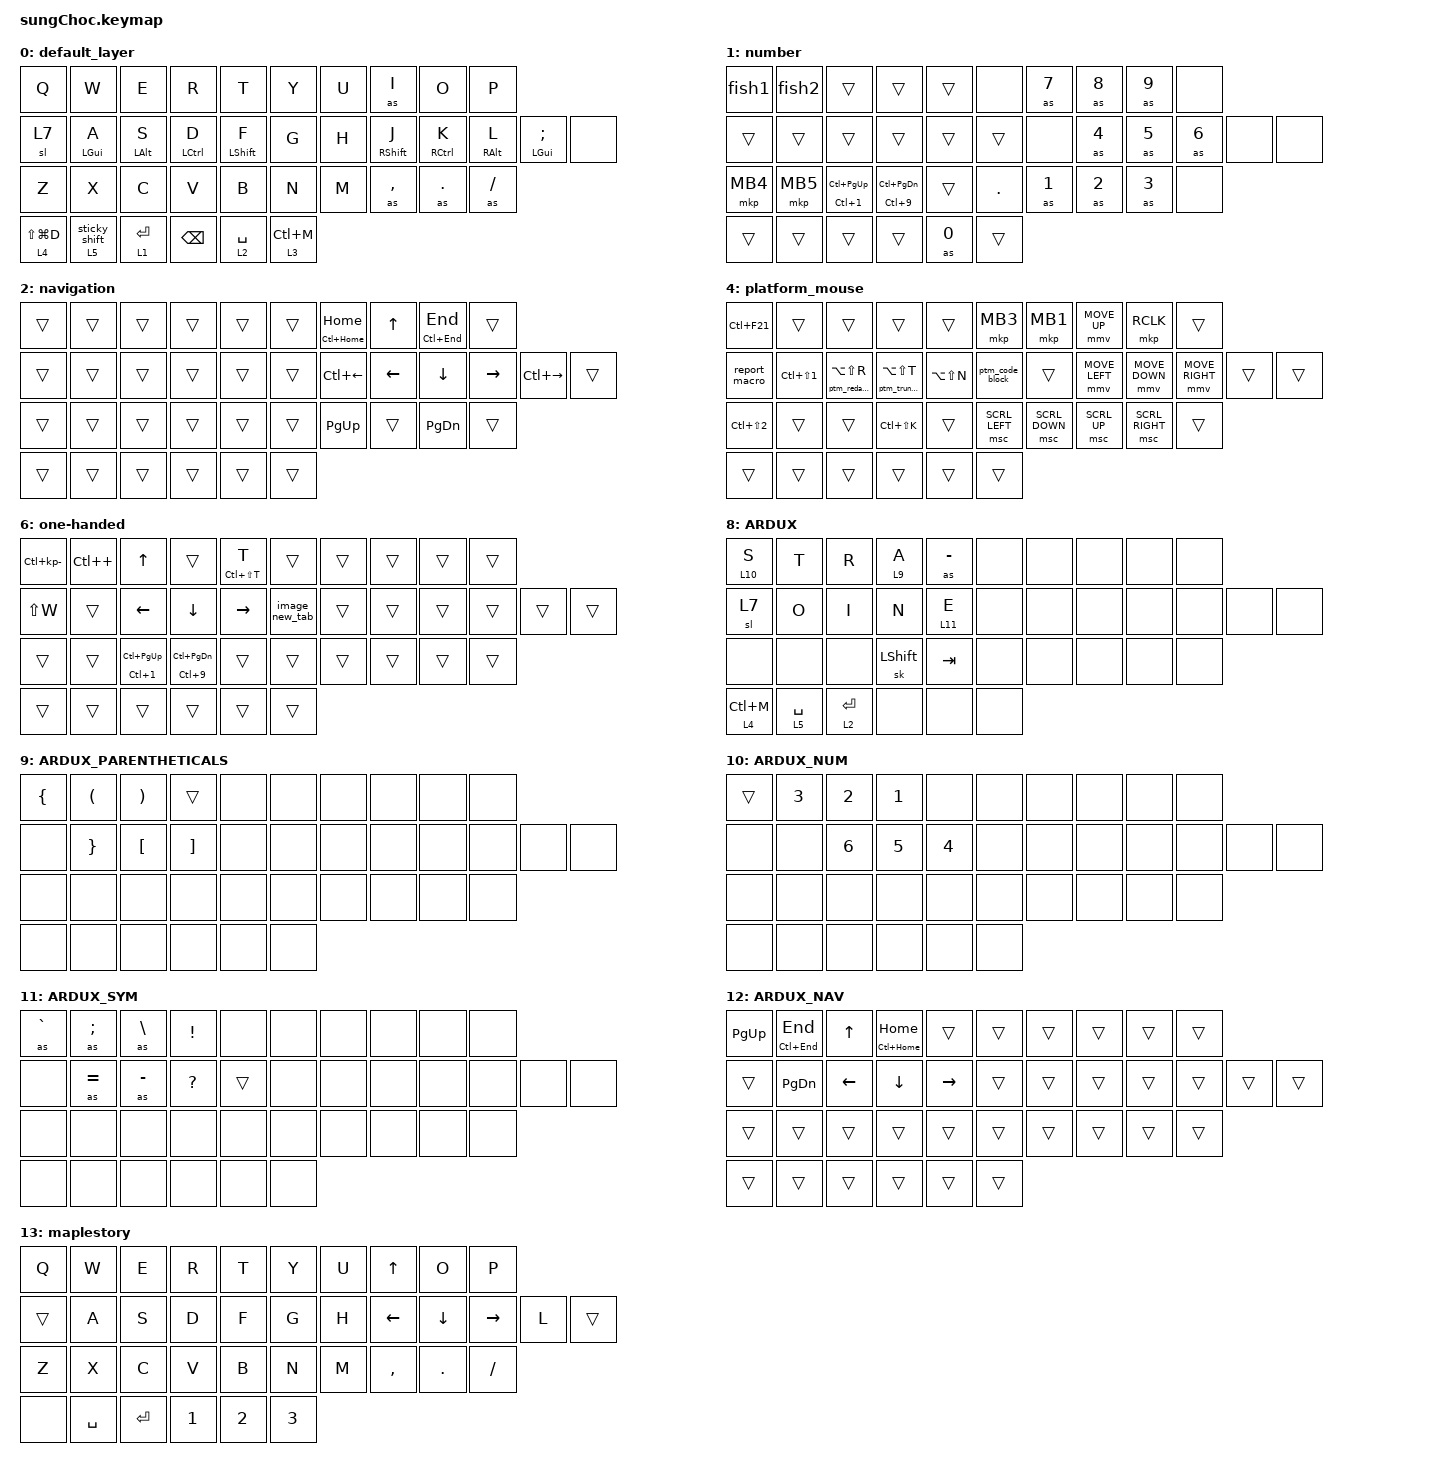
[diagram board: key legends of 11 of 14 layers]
#define ZMK_POINTING_DEFAULT_MOVE_VAL 700  // default: 600
#define ZMK_POINTING_DEFAULT_SCRL_VAL 15    // default: 10

#include <behaviors.dtsi>
#include <dt-bindings/zmk/keys.h>
#include <dt-bindings/zmk/pointing.h>

&sk { quick-release; };

&lt {
    quick-tap-ms = <150>;
    tapping-term-ms = <250>;
};

/ {
    behaviors {
        hrm: hrm {
            compatible = "zmk,behavior-hold-tap";
            label = "HRM";
            bindings = <&kp>, <&kp>;

            #binding-cells = <2>;
            tapping-term-ms = <280>;
            quick-tap-ms = <175>;
            require-prior-idle-ms = <150>;
            flavor = "balanced";
            hold-trigger-on-release;
        };

        ht_layer: ht_layer {
            compatible = "zmk,behavior-hold-tap";
            label = "HT_LAYER";
            bindings = <&mo>, <&kp>;

            #binding-cells = <2>;
            tapping-term-ms = <200>;
            quick-tap-ms = <175>;
            flavor = "tap-preferred";
        };

        hold_tap: hold_tap {
            compatible = "zmk,behavior-hold-tap";
            label = "HOLD_TAP";
            bindings = <&kp>, <&kp>;

            #binding-cells = <2>;
            tapping-term-ms = <180>;
            flavor = "balanced";
        };

        as_ht: auto_shift_hold_tap {
            compatible = "zmk,behavior-hold-tap";
            label = "AUTO_SHIFT_HOLD_TAP";
            bindings = <&shift>, <&kp>;

            #binding-cells = <2>;
            tapping-term-ms = <200>;
            flavor = "balanced";
        };

        burp_rep: burp_rep {
            compatible = "zmk,behavior-tap-dance";
            label = "BURP_REP";
            #binding-cells = <0>;
            bindings = <&kp LC(LS(R))>, <&kp LC(R)>;

            tapping-term-ms = <300>;
        };

        burp_proxy: burp_proxy {
            compatible = "zmk,behavior-tap-dance";
            label = "BURP_PROXY";
            #binding-cells = <0>;
            bindings = <&kp LS(LC(P))>, <&kp LC(T)>;

            tapping-term-ms = <300>;
        };

        burp_org: burp_org {
            compatible = "zmk,behavior-tap-dance";
            label = "BURP_ORG";
            #binding-cells = <0>;
            bindings = <&kp LC(LS(O))>, <&kp LC(O)>;

            tapping-term-ms = <300>;
        };

        burp_int: burp_int {
            compatible = "zmk,behavior-tap-dance";
            label = "BURP_INT";
            #binding-cells = <0>;
            bindings = <&hold_tap LC(P) LC(LS(I))>, <&kp LC(I)>;

            tapping-term-ms = <300>;
        };

        burp_send: burp_send {
            compatible = "zmk,behavior-tap-dance";
            label = "BURP_SEND";
            #binding-cells = <0>;
            bindings = <&kp LC(SPACE)>, <&kp LC(LS(SPACE))>;

            tapping-term-ms = <300>;
        };

        burp_dash: burp_dash {
            compatible = "zmk,behavior-tap-dance";
            label = "BURP_DASH";
            #binding-cells = <0>;
            bindings = <&hold_tap LC(LS(N9)) LS(LC(D))>, <&kp LC(LS(T))>;

            tapping-term-ms = <300>;
        };

        burp_fwd: burp_fwd {
            compatible = "zmk,behavior-tap-dance";
            label = "BURP_FWD";
            #binding-cells = <0>;
            bindings = <&kp LC(F)>, <&kp LC(LS(F))>;

            tapping-term-ms = <300>;
        };

        burp_notes_htmlE: burp_notes_htmlE {
            compatible = "zmk,behavior-tap-dance";
            label = "BURP_NOTES_HTMLE";
            #binding-cells = <0>;
            bindings = <&kp LC(LA(N))>, <&kp LC(LA(H))>;

            tapping-term-ms = <300>;
        };

        ac_vm: ac_vm {
            compatible = "zmk,behavior-tap-dance";
            label = "AC_VM";
            #binding-cells = <0>;
            bindings = <&kp LA(LS(LC(W)))>, <&kp LS(LC(LA(I)))>;
        };

        ac_browser: ac_browser {
            compatible = "zmk,behavior-tap-dance";
            label = "AC_BROWSER";
            #binding-cells = <0>;
            bindings =
                <&hold_tap LC(LA(LS(V))) LC(LA(LS(Q)))>,
                <&kp LA(LS(LC(X)))>;
        };

        truncate: truncate {
            compatible = "zmk,behavior-hold-tap";
            label = "TRUNCATE";
            bindings = <&ptm_truncated>, <&kp>;

            #binding-cells = <2>;
            tapping-term-ms = <180>;
        };

        redact: redact {
            compatible = "zmk,behavior-hold-tap";
            label = "REDACT";
            bindings = <&ptm_redacted>, <&kp>;

            #binding-cells = <2>;
            tapping-term-ms = <180>;
        };

        ptm_code_block: ptm_code_block {
            compatible = "zmk,behavior-tap-dance";
            label = "PTM_CODE_BLOCK";
            #binding-cells = <0>;
            bindings = <&ptm_request>, <&ptm_response>;
        };

        caps: caps {
            compatible = "zmk,behavior-hold-tap";
            label = "CAPS";
            bindings = <&caps_word>, <&sk>;

            #binding-cells = <2>;
            tapping-term-ms = <200>;
            flavor = "balanced";
        };

        ps_at: ps_at {
            compatible = "zmk,behavior-hold-tap";
            label = "PS_AT";
            bindings = <&kp>, <&alt_tab>;

            #binding-cells = <2>;
            tapping-term-ms = <200>;
        };

        burp_rep_with_shift: burp_rep_with_shift {
            compatible = "zmk,behavior-hold-tap";
            label = "BURP_REP_WITH_SHIFT";
            bindings = <&kp>, <&burp_rep>;

            #binding-cells = <2>;
            tapping-term-ms = <200>;
            flavor = "balanced";
        };

        sticky_OS_layer: sticky_OS_layer {
            compatible = "zmk,behavior-hold-tap";
            label = "STICKY_OS_LAYER";
            bindings = <&mo>, <&sl>;

            #binding-cells = <2>;
            tapping-term-ms = <200>;
            flavor = "balanced";
        };

        burp_layer_toggle: burp_layer_toggle {
            compatible = "zmk,behavior-tap-dance";
            label = "BURP_LAYER_TOGGLE";
            #binding-cells = <0>;
            bindings = <&ht_layer 5 A>, <&tog 5>;
        };

        fz_left_both: fz_left_both {
            compatible = "zmk,behavior-hold-tap";
            label = "FZ_LEFT_BOTH";
            bindings = <&kp>, <&fz_left>;

            #binding-cells = <2>;
            tapping-term-ms = <200>;
            flavor = "balanced";
        };

        ardux_sk: ardux_sk {
            compatible = "zmk,behavior-sticky-key";
            label = "ARDUX_SK";
            bindings = <&kp>;
            #binding-cells = <1>;
            release-after-ms = <3000>;
            ignore-modifiers;
        };

        os_shift_layer_change: os_shift_layer_change {
            compatible = "zmk,behavior-hold-tap";
            label = "OS_SHIFT_LAYER_CHANGE";
            bindings = <&mo>, <&sticky_shift>;

            #binding-cells = <2>;
            tapping-term-ms = <200>;
            flavor = "balanced";
        };
    };

    combos {
        compatible = "zmk,combos";

        esc {
            bindings = <&kp ESCAPE>;
            key-positions = <0 1>;
            require-prior-idle-ms = <200>;
            layers = <0 6>;
        };

        tasks {
            bindings = <&kp LC(LA(TAB))>;
            key-positions = <22 24>;
            require-prior-idle-ms = <200>;
        };

        cp {
            bindings = <&kp LC(C)>;
            key-positions = <23 24>;
            require-prior-idle-ms = <200>;
        };

        pst {
            bindings = <&hrm LC(LS(V)) LC(V)>;
            key-positions = <24 25>;
            require-prior-idle-ms = <200>;
        };

        minus {
            bindings = <&as MINUS>;
            key-positions = <8 9 7>;
        };

        quotes {
            bindings = <&as APOS>;
            key-positions = <19 20 18>;
        };

        fwslash {
            bindings = <&as BACKSLASH>;
            key-positions = <30 31 29>;
            require-prior-idle-ms = <200>;
        };

        lbracket {
            bindings = <&as LEFT_BRACKET>;
            key-positions = <3 4>;
            require-prior-idle-ms = <200>;
            layers = <0>;
        };

        rbracket {
            bindings = <&as RIGHT_BRACKET>;
            key-positions = <5 6>;
            require-prior-idle-ms = <200>;
        };

        grave {
            bindings = <&as GRAVE>;
            key-positions = <0 1 2>;
            require-prior-idle-ms = <200>;
            layers = <0>;
        };

        altf4 {
            bindings = <&kp LA(F4)>;
            key-positions = <1 2 3 6 7 8>;
            require-prior-idle-ms = <200>;
        };

        del {
            bindings = <&hold_tap LC(DELETE) DELETE>;
            key-positions = <26 25>;
            require-prior-idle-ms = <200>;
        };

        cut {
            bindings = <&kp LC(X)>;
            key-positions = <25 23>;
        };

        caps {
            bindings = <&caps_word>;
            key-positions = <14 17>;
            require-prior-idle-ms = <200>;
        };

        prscr_at {
            bindings = <&ps_at PRINTSCREEN 0>;
            key-positions = <22 23>;
        };

        select_line {
            bindings = <&select_line>;
            key-positions = <7 8>;
            require-prior-idle-ms = <250>;
        };

        one-handed-layer {
            bindings = <&tog 6>;
            key-positions = <0 1 2 3 6 7 8 9>;
        };

        tab {
            bindings = <&kp TAB>;
            key-positions = <11 12 13>;
            layers = <0>;
            require-prior-idle-ms = <200>;
        };

        lclick_combo {
            bindings = <&mkp LCLK>;
            key-positions = <14 33>;
            require-prior-idle-ms = <150>;
        };

        scroll_down {
            bindings = <&msc SCRL_DOWN>;
            key-positions = <25 33>;
            require-prior-idle-ms = <150>;
        };

        scroll_up {
            bindings = <&msc SCRL_UP>;
            key-positions = <24 33>;
            require-prior-idle-ms = <150>;
        };

        shift_click {
            bindings = <&shift_lclick>;
            key-positions = <14 15>;
            require-prior-idle-ms = <150>;
        };

        virtual_desktop_l {
            bindings = <&kp LC(LG(LEFT_ARROW))>;
            key-positions = <27 28 29>;
            require-prior-idle-ms = <150>;
        };

        virtual_desktop_r {
            bindings = <&kp LC(LG(RIGHT))>;
            key-positions = <28 29 30>;
            require-prior-idle-ms = <150>;
        };

        rclick_combo {
            bindings = <&mkp RCLK>;
            key-positions = <13 33>;
        };

        mclick_combo {
            bindings = <&mkp MCLK>;
            key-positions = <15 33>;
        };

        j_combo {
            bindings = <&kp J>;
            key-positions = <0 1>;
            layers = <8>;
        };

        g_combo {
            bindings = <&kp G>;
            key-positions = <1 2>;
            layers = <8>;
        };

        f_combo {
            bindings = <&kp F>;
            key-positions = <3 2>;
            layers = <8>;
        };

        y_combo {
            bindings = <&kp Y>;
            key-positions = <3 1>;
            layers = <8>;
        };

        u_combo {
            bindings = <&kp U>;
            key-positions = <12 13>;
            layers = <8>;
        };

        c_combo {
            bindings = <&kp C>;
            key-positions = <13 14>;
            layers = <8>;
        };

        v_combo {
            bindings = <&kp V>;
            key-positions = <0 2>;
            layers = <8>;
        };

        k_combo {
            bindings = <&kp K>;
            key-positions = <11 13>;
            layers = <8>;
        };

        h_combo {
            bindings = <&kp H>;
            key-positions = <12 14>;
            layers = <8>;
        };

        w_combo {
            bindings = <&kp W>;
            key-positions = <0 3>;
            layers = <8>;
        };

        b_combo {
            bindings = <&kp B>;
            key-positions = <11 14>;
            layers = <8>;
        };

        x_combo {
            bindings = <&kp X>;
            key-positions = <0 1 2>;
            layers = <8>;
        };

        m_combo {
            bindings = <&kp M>;
            key-positions = <11 12 13>;
            layers = <8>;
        };

        l_combo {
            bindings = <&kp L>;
            key-positions = <13 14 12>;
            layers = <8>;
        };

        q_combo {
            bindings = <&kp Q>;
            key-positions = <0 1 3>;
            layers = <8>;
        };

        p_combo {
            bindings = <&kp P>;
            key-positions = <11 12 14>;
            layers = <8>;
        };

        z_combo {
            bindings = <&kp Z>;
            key-positions = <0 1 2 3>;
            layers = <8>;
        };

        exclamation_combo {
            bindings = <&kp EXCL>;
            key-positions = <1 12>;
            layers = <8>;
        };

        fwslash_combo {
            bindings = <&as SLASH>;
            key-positions = <11 3>;
            layers = <8>;
        };

        period_combo {
            bindings = <&as PERIOD>;
            key-positions = <13 3>;
            layers = <8>;
        };

        comma_combo {
            bindings = <&as COMMA>;
            key-positions = <3 12>;
            layers = <8>;
        };

        quote_combo {
            bindings = <&as SINGLE_QUOTE>;
            key-positions = <3 13 12>;
            layers = <8>;
        };

        seven_combo {
            bindings = <&kp N7>;
            key-positions = <3 2>;
            layers = <10>;
        };

        eight_combo {
            bindings = <&kp N8>;
            key-positions = <2 1>;
            layers = <10>;
        };

        nine_combo {
            bindings = <&kp N9>;
            key-positions = <14 13>;
            layers = <10>;
        };

        zero_combo {
            bindings = <&kp N0>;
            key-positions = <12 13>;
            layers = <10>;
        };

        ARDUX_NAV {
            bindings = <&tog 12>;
            key-positions = <14 2 12>;
            layers = <8 12>;
        };

        backspace_combo {
            bindings = <&hold_tap LC(BACKSPACE) BACKSPACE>;
            key-positions = <14 2>;
            layers = <8>;
        };

        shift_lock {
            bindings = <&kt LEFT_SHIFT>;
            key-positions = <2 13>;
            layers = <8>;
        };

        esc_combo {
            bindings = <&kp ESCAPE>;
            key-positions = <11 2 3>;
            layers = <8>;
        };

        alt_combo {
            bindings = <&sk LEFT_ALT>;
            key-positions = <0 12>;
            layers = <8>;
        };

        gui_combo {
            bindings = <&kp RIGHT_GUI>;
            key-positions = <0 13>;
            layers = <8>;
        };

        toggle_ardux {
            bindings = <&tog 8>;
            key-positions = <27 28 29 30 31>;
        };

        d_combo {
            bindings = <&kp D>;
            key-positions = <2 3 1>;
            layers = <8>;
        };

        eq {
            bindings = <&as EQUAL>;
            key-positions = <31 30>;
            require-prior-idle-ms = <200>;
        };

        maple_switch {
            bindings = <&tog 13>;
            key-positions = <11 12 13 14 17 18 19 20>;
        };
    };

    macros {
        fish1: pw1 {
            compatible = "zmk,behavior-macro";
            #binding-cells = <0>;
            bindings = <&kp N3 &kp A &kp Q &kp H &kp Q &kp C &kp Y &kp B &kp N0 &kp DOT &kp N0 &kp N0>;
            label = "PW1";
        };

        fish2: pw2 {
            compatible = "zmk,behavior-macro";
            #binding-cells = <0>;
            bindings = <&kp N3 &kp A &kp Q &kp H &kp Q &kp C &kp Y &kp B &kp N0 &kp DOT &kp N0>;
            label = "PW2";
        };

        shift: shift {
            compatible = "zmk,behavior-macro-one-param";
            #binding-cells = <1>;
            bindings =
                <&macro_press>,
                <&kp LEFT_SHIFT>,
                <&macro_tap>,
                <&macro_param_1to1 &kp MACRO_PLACEHOLDER>,
                <&macro_release>,
                <&kp LEFT_SHIFT>;

            label = "SHIFT";
        };

        as: as {
            compatible = "zmk,behavior-macro-one-param";
            #binding-cells = <1>;
            bindings =
                <&macro_press>,
                <&macro_param_1to1 &macro_param_1to2 &as_ht MACRO_PLACEHOLDER MACRO_PLACEHOLDER>,
                <&macro_pause_for_release>,
                <&macro_release>,
                <&macro_param_1to1 &macro_param_1to2 &as_ht MACRO_PLACEHOLDER MACRO_PLACEHOLDER>;

            label = "AS";
        };

        ptm_redacted: ptm_redacted {
            compatible = "zmk,behavior-macro";
            #binding-cells = <0>;
            bindings = <&kp LBKT &kp LS(R) &kp LS(E) &kp LS(D) &kp LS(A) &kp LS(C) &kp LS(T) &kp LS(E) &kp LS(D) &kp RBKT>;
            label = "PTM_REDACTED";
        };

        ptm_truncated: ptm_truncated {
            compatible = "zmk,behavior-macro";
            #binding-cells = <0>;
            bindings = <&kp LBKT &kp LS(T) &kp LS(R) &kp LS(U) &kp LS(N) &kp LS(C) &kp LS(A) &kp LS(T) &kp LS(E) &kp LS(D) &kp RBKT>;
            label = "PTM_TRUNCATED";
        };

        ptm_request: ptm_request {
            compatible = "zmk,behavior-macro";
            #binding-cells = <0>;
            bindings = <&kp STAR &kp STAR &kp LS(R) &kp E &kp Q &kp U &kp E &kp S &kp T &kp COLON &kp STAR &kp STAR &kp RET &kp GRAVE &kp GRAVE &kp GRAVE &kp RET &kp RET &kp GRAVE &kp GRAVE &kp GRAVE &kp RET>;
            label = "PTM_REQUEST";
        };

        ptm_response: ptm_response {
            compatible = "zmk,behavior-macro";
            #binding-cells = <0>;
            bindings = <&kp STAR &kp STAR &kp LS(R) &kp E &kp S &kp P &kp O &kp N &kp S &kp E &kp COLON &kp STAR &kp STAR &kp RET &kp GRAVE &kp GRAVE &kp GRAVE &kp RET &kp RET &kp GRAVE &kp GRAVE &kp GRAVE &kp UP_ARROW &kp UP_ARROW &kp UP_ARROW &kp UP_ARROW &kp UP_ARROW>;
            label = "PTM_RESPONSE";
            tap-ms = <25>;
        };

        alt_tab: alt_tab {
            compatible = "zmk,behavior-macro";
            #binding-cells = <0>;
            bindings = <&kt LEFT_ALT &kp TAB &kt LEFT_ALT>;
            label = "ALT_TAB";
            tap-ms = <150>;
        };

        select_line: select_line {
            compatible = "zmk,behavior-macro";
            #binding-cells = <0>;
            bindings = <&kp HOME &kp LS(END)>;
            label = "SELECT_LINE";
            tap-ms = <100>;
        };

        report_macro: report_macro {
            compatible = "zmk,behavior-macro";
            #binding-cells = <0>;
            bindings = <&kp P &kp X &kp ENTER>;
            label = "REPORT_MACRO";
            tap-ms = <200>;
        };

        image_new_tab: image_new_tab {
            compatible = "zmk,behavior-macro";
            #binding-cells = <0>;
            bindings = <&mkp RCLK &kp I>;
            label = "IMAGE_NEW_TAB";
            tap-ms = <400>;
        };

        shift_lclick: shift_lclick {
            compatible = "zmk,behavior-macro";
            #binding-cells = <0>;
            bindings = <&kt LEFT_SHIFT &mkp LCLK &kt LEFT_SHIFT>;
            label = "SHIFT_LCLICK";
        };

        fz_left: fz_left {
            compatible = "zmk,behavior-macro";
            #binding-cells = <0>;
            bindings = <&kt LEFT_GUI &kp LEFT &kt LEFT_GUI>;
            label = "FZ_LEFT";
            tap-ms = <100>;
        };

        sticky_shift: sticky_shift {
            compatible = "zmk,behavior-macro";
            #binding-cells = <0>;
            bindings = <&sk LEFT_SHIFT>;
            label = "STICKY_SHIFT";
        };
    };

    keymap {
        compatible = "zmk,keymap";

        default_layer {
            bindings = <
&kp Q                  &kp W                       &kp E              &kp R          &kp T              &kp Y              &kp U  &as I               &kp O         &kp P
&sl 7                  &hrm LEFT_GUI A             &hrm LEFT_ALT S    &hrm LCTRL D   &hrm LEFT_SHIFT F  &kp G              &kp H  &hrm RIGHT_SHIFT J  &hrm RCTRL K  &hrm RIGHT_ALT L  &hrm LEFT_GUI SEMI  &none
&kp Z                  &kp X                       &kp C              &kp V          &kp B              &kp N              &kp M  &as COMMA           &as DOT       &as SLASH
&ht_layer 4 LS(LG(D))  &os_shift_layer_change 5 0  &ht_layer 1 ENTER  &kp BACKSPACE  &ht_layer 2 SPACE  &ht_layer 3 LC(M)
            >;
        };

        number {
            bindings = <
&fish1    &fish2    &trans                              &trans                          &trans  &none       &as N7        &as N8        &as N9        &none
&trans    &trans    &trans                              &trans                          &trans  &trans      &none         &as NUMBER_4  &as N5        &as NUMBER_6  &none  &none
&mkp MB4  &mkp MB5  &hold_tap LC(NUMBER_1) LC(PAGE_UP)  &hold_tap LC(N9) LC(PAGE_DOWN)  &trans  &kp PERIOD  &as NUMBER_1  &as NUMBER_2  &as NUMBER_3  &none
&trans    &trans    &trans                              &trans                          &as N0  &trans
            >;
        };

        navigation {
            bindings = <
&trans  &trans  &trans  &trans  &trans  &trans  &hold_tap LC(HOME) HOME  &kp UP    &hold_tap LC(END) END  &trans
&trans  &trans  &trans  &trans  &trans  &trans  &kp LC(LEFT)             &kp LEFT  &kp DOWN               &kp RIGHT  &kp LC(RIGHT)  &trans
&trans  &trans  &trans  &trans  &trans  &trans  &kp PAGE_UP              &trans    &kp PAGE_DOWN          &trans
&trans  &trans  &trans  &trans  &trans  &trans
            >;
        };

        media {
            bindings = <
&kp LC(LG(LA(NUMBER_1)))  &kp LG(LA(LC(NUMBER_2)))  &trans                            &trans  &trans  &trans  &kp C_VOLUME_DOWN  &kp C_MUTE      &kp C_VOLUME_UP   &trans
&trans                    &trans                    &fz_left_both LA(LC(LG(LEFT))) 0  &trans  &trans  &trans  &trans             &kp C_PREVIOUS  &kp C_PLAY_PAUSE  &kp C_NEXT  &trans  &trans
&trans                    &trans                    &trans                            &trans  &trans  &trans  &trans             &trans          &trans            &trans
&trans                    &trans                    &trans                            &trans  &trans  &trans
            >;
        };

        platform_mouse {
            bindings = <
&kp LC(F21)           &trans                &trans               &trans                 &trans         &mkp MB3         &mkp MB1        &mmv MOVE_UP    &mkp RCLK        &trans
&report_macro         &kp LC(LS(NUMBER_1))  &redact 0 LA(LS(R))  &truncate 0 LA(LS(T))  &kp LA(LS(N))  &ptm_code_block  &trans          &mmv MOVE_LEFT  &mmv MOVE_DOWN   &mmv MOVE_RIGHT  &trans  &trans
&kp LC(LS(NUMBER_2))  &trans                &trans               &kp LC(LS(K))          &trans         &msc SCRL_LEFT   &msc SCRL_DOWN  &msc SCRL_UP    &msc SCRL_RIGHT  &trans
&trans                &trans                &trans               &trans                 &trans         &trans
            >;
        };

        burp_app_change {
            bindings = <
&hold_tap LC(NUMBER_1) LC(PAGE_UP)  &hold_tap LC(N9) LC(PG_DN)  &mkp RCLK  &mkp LCLK    &mkp MCLK                          &none          &none        &kp LA(LS(LC(G)))  &none                                  &none
&burp_dash                          &burp_org                   &burp_int  &burp_proxy  &burp_rep_with_shift LEFT_SHIFT 0  &kp LS(F13)    &ac_vm       &kp LA(LS(LC(C)))  &kp LA(LS(LC(B)))                      &kp LA(LS(LC(T)))  &kp LA(LS(LC(Z)))  &kp LA(LS(LC(E)))
&burp_notes_htmlE                   &kp LC(LS(L))               &burp_fwd  &burp_send   &msc SCRL_DOWN                     &kp LC(LS(A))  &ac_browser  &kp LC(LA(LS(S)))  &hold_tap LC(LS(LA(O))) LA(LC(LS(P)))  &kp LA(LS(LC(V)))
&sl 4                               &trans                      &sl 7      &trans       &trans                             &trans
            >;
        };

        one-handed {
            bindings = <
&kp LC(KP_MINUS)  &kp LC(PLUS)  &kp UP_ARROW                      &trans                          &hold_tap LC(LS(T)) T  &trans          &trans  &trans  &trans  &trans
&kp LS(W)         &trans        &kp LEFT                          &kp DOWN                        &kp RIGHT              &image_new_tab  &trans  &trans  &trans  &trans  &trans  &trans
&trans            &trans        &hold_tap LC(NUMBER_1) LC(PG_UP)  &hold_tap LC(N9) LC(PAGE_DOWN)  &trans                 &trans          &trans  &trans  &trans  &trans
&trans            &trans        &trans                            &trans                          &trans                 &trans
            >;
        };

        left_app_change {
            bindings = <
&trans             &trans                                 &kp LA(LS(LC(G)))  &trans             &trans             &trans  &trans  &trans  &trans  &trans
&kp LC(LA(LS(E)))  &kp LC(LA(LS(Z)))                      &kp LC(LA(LS(T)))  &kp LC(LS(LA(B)))  &kp LC(LA(LS(C)))  &ac_vm  &trans  &trans  &trans  &trans  &trans  &trans
&kp LC(LA(LS(V)))  &hold_tap LA(LS(LC(O))) LA(LS(LC(P)))  &kp LA(LS(LC(S)))  &ac_browser        &kp LS(LC(A))      &trans  &trans  &trans  &trans  &trans
&trans             &trans                                 &trans             &trans             &trans             &trans
            >;
        };

        ARDUX {
            bindings = <
&lt 10 S           &kp T              &kp R              &lt 9 A         &as MINUS  &none  &none  &none  &none  &none
&sl 7              &kp O              &kp I              &kp N           &lt 11 E   &none  &none  &none  &none  &none  &none  &none
&none              &none              &none              &sk LEFT_SHIFT  &kp TAB    &none  &none  &none  &none  &none
&ht_layer 4 LC(M)  &ht_layer 5 SPACE  &ht_layer 2 ENTER  &none           &none      &none
            >;
        };

        ARDUX_PARENTHETICALS {
            bindings = <
&kp LEFT_BRACE  &kp LEFT_PARENTHESIS  &kp RIGHT_PARENTHESIS  &trans             &none  &none  &none  &none  &none  &none
&none           &kp RIGHT_BRACE       &kp LEFT_BRACKET       &kp RIGHT_BRACKET  &none  &none  &none  &none  &none  &none  &none  &none
&none           &none                 &none                  &none              &none  &none  &none  &none  &none  &none
&none           &none                 &none                  &none              &none  &none
            >;
        };

        ARDUX_NUM {
            bindings = <
&trans  &kp N3  &kp N2  &kp N1  &none   &none  &none  &none  &none  &none
&none   &none   &kp N6  &kp N5  &kp N4  &none  &none  &none  &none  &none  &none  &none
&none   &none   &none   &none   &none   &none  &none  &none  &none  &none
&none   &none   &none   &none   &none   &none
            >;
        };

        ARDUX_SYM {
            bindings = <
&as GRAVE  &as SEMI   &as BSLH   &kp EXCL   &none   &none  &none  &none  &none  &none
&none      &as EQUAL  &as MINUS  &kp QMARK  &trans  &none  &none  &none  &none  &none  &none  &none
&none      &none      &none      &none      &none   &none  &none  &none  &none  &none
&none      &none      &none      &none      &none   &none
            >;
        };

        ARDUX_NAV {
            bindings = <
&kp PG_UP  &hold_tap LC(END) END  &kp UP_ARROW  &hold_tap LC(HOME) HOME  &trans     &trans  &trans  &trans  &trans  &trans
&trans     &kp PAGE_DOWN          &kp LEFT      &kp DOWN_ARROW           &kp RIGHT  &trans  &trans  &trans  &trans  &trans  &trans  &trans
&trans     &trans                 &trans        &trans                   &trans     &trans  &trans  &trans  &trans  &trans
&trans     &trans                 &trans        &trans                   &trans     &trans
            >;
        };

        maplestory {
            bindings = <
&kp Q   &kp W      &kp E      &kp R   &kp T   &kp Y   &kp U  &kp UP_ARROW  &kp O     &kp P
&trans  &kp A      &kp S      &kp D   &kp F   &kp G   &kp H  &kp LEFT      &kp DOWN  &kp RIGHT  &kp L  &trans
&kp Z   &kp X      &kp C      &kp V   &kp B   &kp N   &kp M  &kp COMMA     &kp DOT   &kp FSLH
&none   &kp SPACE  &kp ENTER  &kp N1  &kp N2  &kp N3
            >;
        };
    };
};
